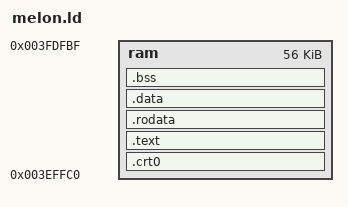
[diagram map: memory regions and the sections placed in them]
/*--------------------------------------------------------------------------------
	This Source Code Form is subject to the terms of the Mozilla Public License,
	v. 2.0. If a copy of the MPL was not distributed with this file, You can
	obtain one at https://mozilla.org/MPL/2.0/.
--------------------------------------------------------------------------------*/
OUTPUT_FORMAT("elf32-littlearm", "elf32-bigarm", "elf32-littlearm")
OUTPUT_ARCH(arm)
ENTRY(_start)

MEMORY
{
    ram : ORIGIN = 0x3EFFC0, LENGTH = 0xE000
}

__ram_end	=	0x3FFFFC;
__eheap_end	=	0x3FFFFC;
__ram_length = LENGTH(ram);

__sp_svc	=	__ram_end;
__sp_irq	=	__sp_svc - 0x100;
__sp_usr	=	__sp_irq - 0x100;

PHDRS
{
	main    PT_LOAD FLAGS(7);
}

SECTIONS
{
	.crt0	:
	{
		__text_start = . ;
		KEEP (*(.crt0))
		. = ALIGN(4);  /* REQUIRED. LD is flaky without it. */
	} >ram :main = 0x00

	.text :   /* ALIGN (4): */
	{
		*(.text)
		*(.stub)
		*(.text.*)
		/* .gnu.warning sections are handled specially by elf32.em.  */
		*(.gnu.warning)
		*(.gnu.linkonce.t*)
		*(.glue_7)
		*(.glue_7t)
		. = ALIGN(4);  /* REQUIRED. LD is flaky without it. */
	} >ram :main = 0xff

	__text_end = . ;

	.rodata :
	{
		*(.rodata)
		*all.rodata*(*)
		*(.roda)
		*(.rodata.*)
		*(.gnu.linkonce.r*)
		SORT(CONSTRUCTORS)
		. = ALIGN(4);   /* REQUIRED. LD is flaky without it. */
	} >ram :main = 0xff

	.data ALIGN(4) :
	{
		__data_start = ABSOLUTE(.);
		*(.data)
		*(.data.*)
		*(.gnu.linkonce.d*)
		CONSTRUCTORS
		. = ALIGN(4);
		__data_end = ABSOLUTE(.) ;
	} >ram :main = 0xff

	__bss_vma = . ;

	.bss __bss_vma (NOLOAD):
	{
		__bss_start = ABSOLUTE(.);
		__bss_start__ = ABSOLUTE(.);
		*(.dynbss)
		*(.gnu.linkonce.b*)
		*(.bss*)
		*(COMMON)
		. = ALIGN(4);    /* REQUIRED. LD is flaky without it. */
		__bss_end__ = ABSOLUTE(.) ;
		__end__ = ABSOLUTE(.) ;
	} >ram :NONE
}
